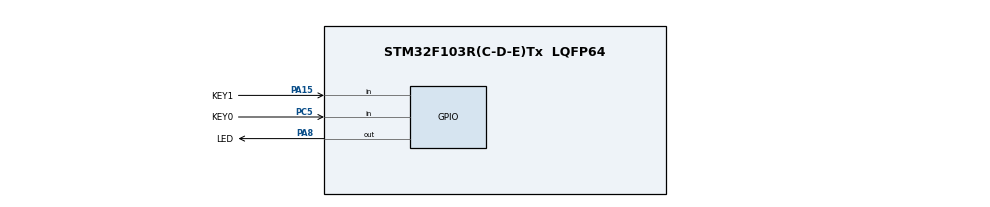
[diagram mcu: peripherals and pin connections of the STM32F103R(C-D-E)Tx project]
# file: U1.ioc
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Mcu.Family=STM32F1
Mcu.Name=STM32F103R(C-D-E)Tx
Mcu.Package=LQFP64
NVIC.PriorityGroup=NVIC_PRIORITYGROUP_4
PA15.GPIO_Label=KEY1
PA15.GPIO_PuPd=GPIO_PULLUP
PA15.Signal=GPIO_Input
PA8.GPIO_Label=LED
PA8.Signal=GPIO_Output
PC5.GPIO_Label=KEY0
PC5.GPIO_PuPd=GPIO_PULLUP
PC5.Signal=GPIO_Input
ProjectManager.HeapSize=0x200
ProjectManager.StackSize=0x400
ProjectManager.TargetToolchain=SW4STM32
RCC.APB1Freq_Value=8000000
RCC.APB2Freq_Value=8000000
VP_SYS_VS_ND.Mode=No_Debug
board=custom

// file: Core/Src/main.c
/* USER CODE BEGIN Header */
/**
  ******************************************************************************
  * @file           : main.c
  * @brief          : Main program body
  ******************************************************************************
  * @attention
  *
  * <h2><center>&copy; Copyright (c) 2021 STMicroelectronics.
  * All rights reserved.</center></h2>
  *
  * This software component is licensed by ST under BSD 3-Clause license,
  * the "License"; You may not use this file except in compliance with the
  * License. You may obtain a copy of the License at:
  *                        opensource.org/licenses/BSD-3-Clause
  *
  ******************************************************************************
  */
/* USER CODE END Header */
#include "main.h"
#include "gpio.h"

void SystemClock_Config(void);

int main(void) {

    /* MCU Configuration--------------------------------------------------------*/

    /* Reset of all peripherals, Initializes the Flash interface and the Systick. */
    HAL_Init();

    /* Configure the system clock */
    SystemClock_Config();

    /* Initialize all configured peripherals */
    MX_GPIO_Init();

    /* Infinite loop */
    /* USER CODE BEGIN WHILE */
    char flag = 0, flag1 = 0, bt = 0;
    while (1) {
        if (HAL_GPIO_ReadPin(KEY0_GPIO_Port, KEY0_Pin) == GPIO_PIN_RESET) {
            bt = 0;
            flag = 1;
        } else {
            flag = 0;
        }
        if (HAL_GPIO_ReadPin(KEY1_GPIO_Port, KEY1_Pin) == GPIO_PIN_RESET) {
            bt = 1;
            if (flag1 != 2) {
                flag1 = 1;
            }
        } else {
            flag1 = 0;
        }
        if (bt == 0) {
            if (flag == 1) {
                HAL_GPIO_WritePin(LED_GPIO_Port, LED_Pin, GPIO_PIN_RESET);
            } else {
                HAL_GPIO_WritePin(LED_GPIO_Port, LED_Pin, GPIO_PIN_SET);
            }
        }
        if (bt == 1) {
            if (flag1 == 1) {
                HAL_GPIO_TogglePin(LED_GPIO_Port, LED_Pin);
                flag1 = 2;
            }
        }

//        if(HAL_GPIO_ReadPin(KEY0_GPIO_Port,KEY0_Pin)==GPIO_PIN_RESET){
//            HAL_Delay(20);
//            if(HAL_GPIO_ReadPin(KEY0_GPIO_Port,KEY0_Pin)==GPIO_PIN_RESET){
//            HAL_GPIO_WritePin(LED_GPIO_Port,LED_Pin,GPIO_PIN_RESET);
//        }
//        while(HAL_GPIO_ReadPin(KEY0_GPIO_Port,KEY0_Pin)==GPIO_PIN_RESET);
//            HAL_GPIO_WritePin(LED_GPIO_Port,LED_Pin,GPIO_PIN_SET);
//        }
//
//      if(HAL_GPIO_ReadPin(KEY1_GPIO_Port,KEY1_Pin)==GPIO_PIN_RESET){
//          HAL_Delay(20);
//          if(HAL_GPIO_ReadPin(KEY1_GPIO_Port,KEY1_Pin)==GPIO_PIN_RESET){
//              HAL_GPIO_TogglePin(LED_GPIO_Port,LED_Pin);
//          }
//          while(HAL_GPIO_ReadPin(KEY1_GPIO_Port,KEY1_Pin)==GPIO_PIN_RESET);
//      }
        /* USER CODE END WHILE */

    }
}

void SystemClock_Config(void) {
    RCC_OscInitTypeDef RCC_OscInitStruct = {0};
    RCC_ClkInitTypeDef RCC_ClkInitStruct = {0};

    /** Initializes the RCC Oscillators according to the specified parameters
    * in the RCC_OscInitTypeDef structure.
    */
    RCC_OscInitStruct.OscillatorType = RCC_OSCILLATORTYPE_HSI;
    RCC_OscInitStruct.HSIState = RCC_HSI_ON;
    RCC_OscInitStruct.HSICalibrationValue = RCC_HSICALIBRATION_DEFAULT;
    RCC_OscInitStruct.PLL.PLLState = RCC_PLL_NONE;
    if (HAL_RCC_OscConfig(&RCC_OscInitStruct) != HAL_OK) {
        Error_Handler();
    }
    /** Initializes the CPU, AHB and APB buses clocks
    */
    RCC_ClkInitStruct.ClockType = RCC_CLOCKTYPE_HCLK | RCC_CLOCKTYPE_SYSCLK
                                  | RCC_CLOCKTYPE_PCLK1 | RCC_CLOCKTYPE_PCLK2;
    RCC_ClkInitStruct.SYSCLKSource = RCC_SYSCLKSOURCE_HSI;
    RCC_ClkInitStruct.AHBCLKDivider = RCC_SYSCLK_DIV1;
    RCC_ClkInitStruct.APB1CLKDivider = RCC_HCLK_DIV1;
    RCC_ClkInitStruct.APB2CLKDivider = RCC_HCLK_DIV1;

    if (HAL_RCC_ClockConfig(&RCC_ClkInitStruct, FLASH_LATENCY_0) != HAL_OK) {
        Error_Handler();
    }
}

void Error_Handler(void) {
    __disable_irq();
    while (1) {
    }
}

/************************ (C) COPYRIGHT STMicroelectronics *****END OF FILE****/
